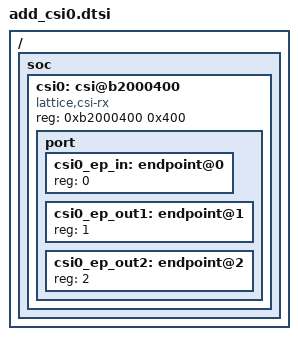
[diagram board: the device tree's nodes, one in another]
/*
 * Copyright (c) 2025 tinyVision.ai Inc.
 *
 * SPDX-License-Identifier: Apache-2.0
 */

/ {
	soc {
		csi0: csi@b2000400 {
			compatible = "lattice,csi-rx";
			reg = <0xb2000400 0x400>;

			port {
				#address-cells = <1>;
				#size-cells = <0>;

				csi0_ep_in: endpoint@0 {
					reg = <0>;
				};

				csi0_ep_out1: endpoint@1 {
					reg = <1>;
				};

				csi0_ep_out2: endpoint@2 {
					reg = <2>;
				};
			};
		};
	};
};
